# K1921VK01T register map
Vendor: NIIET; Series: K1921VKx; File version: 2.2
CPU: CM4 r0p1, little endian, MPU, FPU, 3 interrupt priority bits
Registers are 32-bit, read-write, reset 0x0 unless marked. A register's access mark holds for its fields unless they carry their own. Offsets are from the block's base; [hi:lo] are bit positions; {n}, {i} and the like mark numbered series; 'fields as' and 'values as' point back to an identical list.

## NT_ETHERNET — ETHERNET controller registers
Base 0x80080000
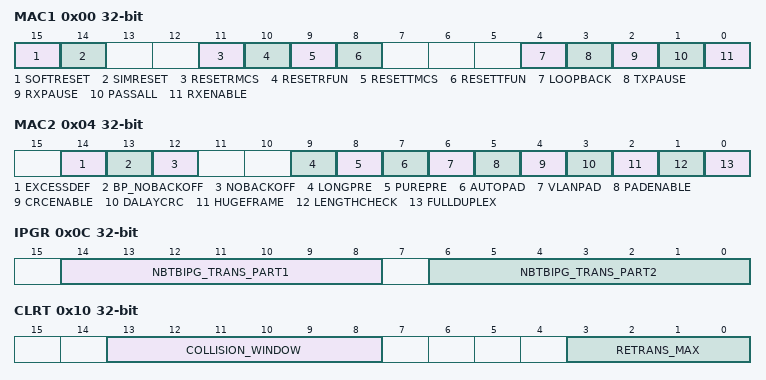
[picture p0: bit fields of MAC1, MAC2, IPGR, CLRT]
0x00 MAC1 — MAC configuration register 1
  [15] SOFTRESET — Reset bit block MAC Ethernet Controller
  [14] SIMRESET — Reset bit random number generator transmitting device
  [11] RESETRMCS — Reset bit device MAC layer, responsible for managing the filtering addresses of packets received
  [10] RESETRFUN — Reset bit logic devices receive packets
  [9] RESETTMCS — Reset bit device MAC layer, responsible for managing addresses in information transmission Reset bit device MAC layer, responsible for managing addresses in information transmission
  [8] RESETTFUN — Reset bit logic devices packet
  [4] LOOPBACK — Bit activate reception of packets transmitted back through MACReceive-interface
  [3] TXPAUSE — Enable transmission pauses Frame
  [2] RXPAUSE — Enable receiving a pause as part of Frame
  [1] PASSALL — Bit control PASS
  [0] RXENABLE — Frame reception enable bit
0x04 MAC2 — MAC configuration register 2
  [14] EXCESSDEF — Mode Select bit packet processing
  [13] BP_NOBACKOFF — Enable bit retransmission in conflict
  [12] NOBACKOFF — Bit parameter setting retransmission in conflict
  [9] LONGPRE — Select bit preamble length packets received
  [8] PUREPRE — Bit enable validation preamble
  [7] AUTOPAD — Bit enable automatic determination of type Frame
  [6] VLANPAD — Enable bit short additions Frame
  [5] PADENABLE — Bit resolution and functioning bits AUTOPAD VLANPAD
  [4] CRCENABLE — Enable bit CRC inserter
  [3] DALAYCRC — Enable bit adding a 4-byte CRC
  [2] HUGEFRAME — Enable Bit Frame reception and transmission of arbitrary length
  [1] LENGTHCHECK — Enable bit komparatsii length Frame
  [0] FULLDUPLEX — Mode Select bit MAC-run operations
0x08 IPGT — Register Back-to-Back Inter-Packet-Gap
  [6:0] BTBIPG_TRANS
0x0C IPGR — Register Non-Back-to-Back Inter-Packet-Gap
  [14:8] NBTBIPG_TRANS_PART1, [6:0] NBTBIPG_TRANS_PART2
0x10 CLRT — Register collision window
  [13:8] COLLISION_WINDOW, [3:0] RETRANS_MAX
0x14 MAXF — Register the upper limit size Frame
  [15:0] MAXFRAME_LENGTH
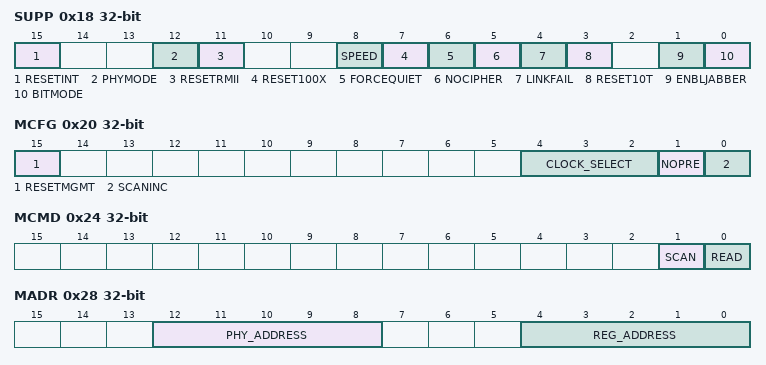
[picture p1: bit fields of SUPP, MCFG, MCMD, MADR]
0x18 SUPP — Register PHY-support interface
  [15] RESETINT — Reset bit of the physical interface
  [12] PHYMODE — Bit configuration consistent with MI SMII-connected devices
  [11] RESETRMII — Reset bit simplified logic MII
  [8] SPEED — Bits set the operating speed simplified MII
  [7] RESET100X — Reset bit of the module that contains the logic of the encoder / decoder bit characters 4/5 bits
  [6] FORCEQUIET — enable encryption
  [5] NOCIPHER — Select encryption
  [4] LINKFAIL — Bit resolution modeling
  [3] RESET10T — Reset bit module, which converts the MII nibble streams into a serial bit stream mode transceiver 10T
  [1] ENBLJABBER — Enable bit of protection against incorrect data transmission mode 10T ENDEC
  [0] BITMODE — Activated mode 10BASE-T ENDEC
0x20 MCFG — Configuration control register MII
  [15] RESETMGMT — Reset bit MII management module
  [4:2] CLOCK_SELECT
    0=Div4 (1/4 divider); 2=Div6 (1/6 divider); 3=Div8 (1/8 divider); 4=Div10 (1/10 divider); 5=Div14 (1/14 divider); 6=Div20 (1/20 divider); 7=Div28 (1/28 divider)
  [1] NOPRE — Control bit preamble
  [0] SCANINC — Reading module addresses all MII PHY
0x24 MCMD — Command register MII
  [1] SCAN — Continuous performance of read cycles
  [0] READ — Single execution of read cycles
0x28 MADR — MII address register
  [12:8] PHY_ADDRESS, [4:0] REG_ADDRESS
0x2C MWTD — Register data written in MII
  [15:0] WRITE_DATA wo
0x30 MRDD — Register read data from MII
  [15:0] READ_DATA ro
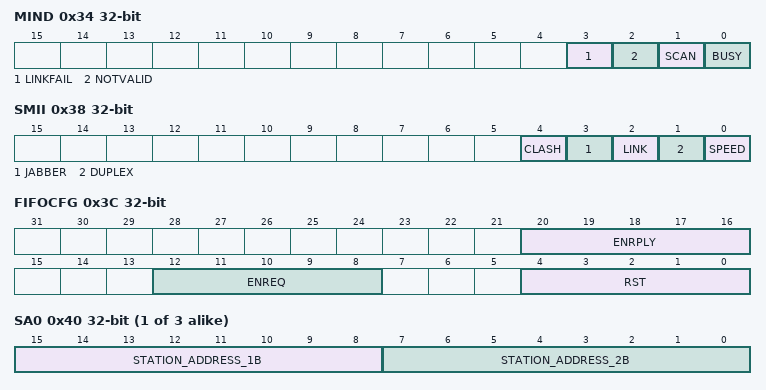
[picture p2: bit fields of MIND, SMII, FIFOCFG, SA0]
0x34 MIND wo — MII status register flags
  [3] LINKFAIL ro — Failure flag control MII (PHY device management)
  [2] NOTVALID ro — Flag unfinished read cycle MII (inaccessibility of data to be read)
  [1] SCAN ro — Flag ongoing scan operation (continue reading cycles control MII)
  [0] BUSY ro — Flag continuing cycle of the read / write control MII
0x38 SMII ro — MII controller status register
  [4] CLASH — Flag of the selected mode
  [3] JABBER — Flag of conditions Jabber
  [2] LINK — Status Indicator LINK
  [1] DUPLEX — Mode indicator
  [0] SPEED — Speed Indicator
0x3C FIFOCFG — MIIFIFO configurate register
  [20:16] ENRPLY ro — Indicate enable MIIFIFO
    on read: 0=disable MIIFIFO modules; 31=enable MIIFIFO modules
  [12:8] ENREQ — Enable request MIIFIFO
    0=disable MIIFIFO requests; 31=enable MIIFIFO requests
  [4:0] RST — Reset MIIFIFO
{0x40+4i} SA{i} (i=0..2) — Station address register {i}
  [15:8] STATION_ADDRESS_{2i+1}B, [7:0] STATION_ADDRESS_{2i+2}B
0x180 DMATxCtrl — Reception control register
  [0] RXENABLE — Enable bit DMA device to receive packets
0x184 DMATxDescriptor — Reception descriptor pointer register
  [31:2] DADDR
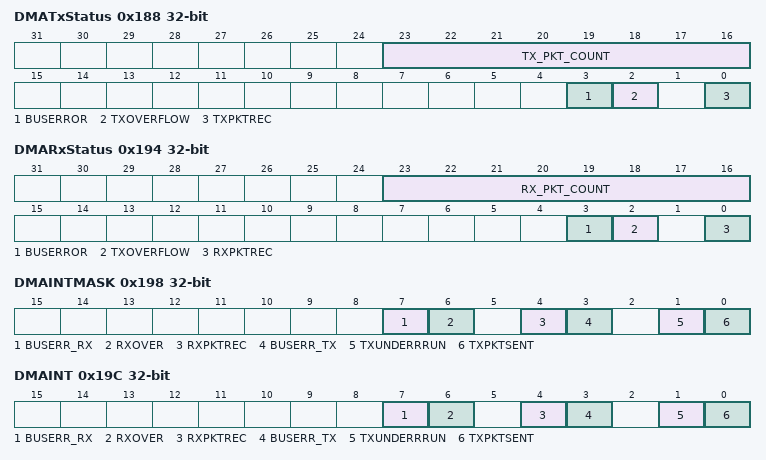
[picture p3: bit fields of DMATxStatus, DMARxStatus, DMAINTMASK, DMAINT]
0x188 DMATxStatus — Status transmission register
  [23:16] TX_PKT_COUNT
  [3] BUSERROR — Flag a bus error
  [2] TXOVERFLOW — Data Indicator
  [0] TXPKTREC — Flag successfully transmit one or more packets
0x18C DMARxCtrl — Control receive register
  [0] RXENABLE — Enable receive
0x190 DMARxDescriptor — Pointer receive descriptor register
  [31:2] DADDR
0x194 DMARxStatus — Status receiving register
  [23:16] RX_PKT_COUNT
  [3] BUSERROR — Flag a bus error
  [2] TXOVERFLOW — Data Indicator
  [0] RXPKTREC — Flag successfully receive one or more packets
0x198 DMAINTMASK — Mask interrupt register
  [7] BUSERR_RX ro, [6] RXOVER ro, [4] RXPKTREC ro, [3] BUSERR_TX ro, [1] TXUNDERRRUN ro, [0] TXPKTSENT ro
0x19C DMAINT — Interrupt register
  fields as DMAINTMASK
